# STM32L412C8T6 register map
File version: 1.0
Registers are 32-bit, access not given, reset 0x0 unless marked. A register's access mark holds for its fields unless they carry their own. Offsets are from the block's base; [hi:lo] are bit positions.

## RCC
Base 0x40021000
0x00 CR
  [27] PLLSAI1RDY, [26] PLLSAI1ON, [25] PLLRDY, [24] PLLON, [19] CSSON, [18] HSEBYP, [17] HSERDY, [16] HSEON, [31:12] s, [11] HSIASFS, [10] HSIRDY, [9] HSIKERON, [8] HSION, [7:4] MSIRANGE, [3] MSIRGSEL, [2] MSIPLLEN, [1] MSIRDY, [0] MSION
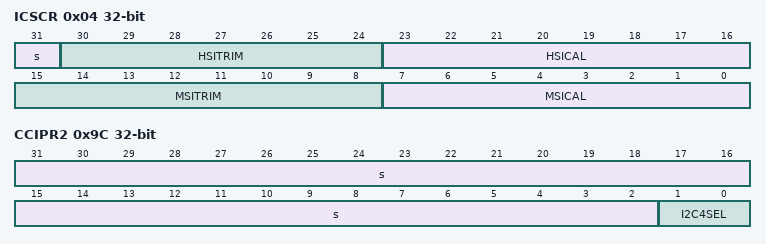
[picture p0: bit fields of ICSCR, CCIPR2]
0x04 ICSCR
  [31] s, [30:24] HSITRIM, [23:16] HSICAL, [15:8] MSITRIM, [7:0] MSICAL
0x08 CFGR
  [30:28] MCOPRE, [27:24] MCOSEL, [15] STOPWUCK, [31:14] s, [13:11] PPRE2, [10:8] PPRE1, [7:4] HPRE, [3:2] SWS, [1:0] SW
0x0C PLLCFGR
  [31:27] PLLPDIV, [26:25] PLLR, [24] PLLREN, [22:21] PLLQ, [20] PLLQEN, [17] PLLP, [16] PLLPEN, [14:8] PLLN, [6:4] PLLM, [23:2] s, [1:0] PLLSRC
0x10 PLLSAI1CFGR
  [31:27] PLLSAI1PDIV, [26:25] PLLSAI1R, [24] PLLSAI1REN, [22:21] PLLSAI1Q, [20] PLLSAI1QEN, [17] PLLSAI1P, [16] PLLSAI1PEN, [14:8] PLLSAI1N, [23:0] s
0x18 CIER
  [10] HSI48RDYIE, [9] LSECSSIE, [31:7] s, [6] PLLSAI1RDYIE, [5] PLLRDYIE, [4] HSERDYIE, [3] HSIRDYIE, [2] MSIRDYIE, [1] LSERDYIE, [0] LSIRDYIE
0x1C CIFR
  [10] HSI48RDYF, [9] LSECSSF, [8] CSSF, [31:7] s, [6] PLLSAI1RDYF, [5] PLLRDYF, [4] HSERDYF, [3] HSIRDYF, [2] MSIRDYF, [1] LSERDYF, [0] LSIRDYF
0x20 CICR
  [10] HSI48RDYC, [9] LSECSSC, [8] CSSC, [31:7] s, [6] PLLSAI1RDYC, [5] PLLRDYC, [4] HSERDYC, [3] HSIRDYC, [2] MSIRDYC, [1] LSERDYC, [0] LSIRDYC
0x28 AHB1RSTR
  [16] TSCRST, [12] CRCRST, [8] FLASHRST, [31:2] s, [1] DMA2RST, [0] DMA1RST
0x2C AHB2RSTR
  [18] RNGRST, [16] AESRST, [13] ADCRST, [7] GPIOHRST, [31:5] s, [4] GPIOERST, [3] GPIODRST, [2] GPIOCRST, [1] GPIOBRST, [0] GPIOARST
0x30 AHB3RSTR
  [8] QSPIRST, [31:0] s
0x38 APB1RSTR1
  [31] LPTIM1RST, [30] OPAMPRST, [29] DAC1RST, [28] PWRRST, [26] USBFSRST, [25] CAN1RST, [24] CRSRST, [23] I2C3RST, [22] I2C2RST, [21] I2C1RST, [19] UART4RST, [18] USART3RST, [17] USART2RST, [15] SPI3RST, [14] SPI2RST, [9] LCDRST, [5] TIM7RST, [4] TIM6RST, [27:2] s, [1] TIM3RST, [0] TIM2RST
0x3C APB1RSTR2
  [5] LPTIM2RST, [31:3] s, [2] SWPMI1RST, [1] I2C4RST, [0] LPUART1RST
0x40 APB2RSTR
  [24] DFSDM1RST, [21] SAI1RST, [17] TIM16RST, [16] TIM15RST, [14] USART1RST, [12] SPI1RST, [11] TIM1RST, [10] SDMMC1RST, [31:1] s, [0] SYSCFGRST
0x48 AHB1ENR
  [16] TSCEN, [12] CRCEN, [8] FLASHEN, [31:2] s, [1] DMA2EN, [0] DMA1EN
0x4C AHB2ENR
  [18] RNGEN, [16] AESEN, [13] ADCEN, [7] GPIOHEN, [31:5] s, [4] GPIOEEN, [3] GPIODEN, [2] GPIOCEN, [1] GPIOBEN, [0] GPIOAEN
0x50 AHB3ENR
  [8] QSPIEN, [31:1] s
0x58 APB1ENR1
  [31] LPTIM1EN, [30] OPAMPEN, [29] DAC1EN, [28] PWREN, [26] USBFSEN, [25] CAN1EN, [24] CRSEN, [23] I2C3EN, [22] I2C2EN, [21] I2C1EN, [19] UART4EN, [18] USART3EN, [17] USART2EN, [15] SP3EN, [14] SPI2EN, [11] WWDGEN, [10] RTCAPBEN, [9] LCDEN, [5] TIM7EN, [4] TIM6EN, [27:2] s, [1] TIM3EN, [0] TIM2EN
0x5C APB1ENR2
  [5] LPTIM2EN, [31:3] s, [2] SWPMI1EN, [1] I2C4EN, [0] LPUART1EN
0x60 APB2ENR
  [24] DFSDM1EN, [21] SAI1EN, [17] TIM16EN, [16] TIM15EN, [14] USART1EN, [12] SPI1EN, [11] TIM1EN, [10] SDMMC1EN, [7] FWEN, [31:1] s, [0] SYSCFGEN
0x68 AHB1SMENR
  [16] TSCSMEN, [12] CRCSMEN, [9] SRAM1SMEN, [8] FLASHSMEN, [31:2] s, [1] DMA2SMEN, [0] DMA1SMEN
0x6C AHB2SMENR
  [18] RNGSMEN, [16] AESSMEN, [13] ADCFSSMEN, [9] SRAM2SMEN, [7] GPIOHSMEN, [31:5] s, [4] GPIOESMEN, [3] GPIODSMEN, [2] GPIOCSMEN, [1] GPIOBSMEN, [0] GPIOASMEN
0x70 AHB3SMENR
  [8] QSPISMEN, [31:0] s
0x78 APB1SMENR1
  [31] LPTIM1SMEN, [30] OPAMPSMEN, [29] DAC1SMEN, [28] PWRSMEN, [26] USBFSSMEN, [25] CAN1SMEN, [24] CRSSMEN, [23] I2C3SMEN, [22] I2C2SMEN, [21] I2C1SMEN, [19] UART4SMEN, [18] USART3SMEN, [17] USART2SMEN, [15] SP3SMEN, [14] SPI2SMEN, [11] WWDGSMEN, [10] RTCAPBSMEN, [9] LCDSMEN, [5] TIM7SMEN, [4] TIM6SMEN, [27:2] s, [1] TIM3SMEN, [0] TIM2SMEN
0x7C APB1SMENR2
  [5] LPTIM2SMEN, [31:3] s, [2] SWPMI1SMEN, [1] I2C4SMEN, [0] LPUART1SMEN
0x80 APB2SMENR
  [24] DFSDM1SMEN, [21] SAI1SMEN, [17] TIM16SMEN, [16] TIM15SMEN, [14] USART1SMEN, [12] SPI1SMEN, [11] TIM1SMEN, [10] SDMMC1SMEN, [31:1] s, [0] SYSCFGSMEN
0x88 CCIPR
  [31] DFSDM1SEL, [30] SWPMI1SEL, [29:28] ADCSEL, [27:26] CLK48SEL, [23:22] SAI1SEL, [21:20] LPTIM2SEL, [19:18] LPTIM1SEL, [17:16] I2C3SEL, [15:14] I2C2SEL, [13:12] I2C1SEL, [11:10] LPUART1SEL, [25:8] s, [7:6] UART4SEL, [5:4] USART3SEL, [3:2] USART2SEL, [1:0] USART1SEL
0x90 BDCR
  [25] LSCOSEL, [24] LSCOEN, [16] BDRST, [15] RTCEN, [31:10] s, [9:8] RTCSEL, [7] LSESYSDIS, [6] LSECSSD, [5] LSECSSON, [4:3] LSEDRV, [2] LSEBYP, [1] LSERDY, [0] LSEON
0x94 CSR
  [31] LPWRRSTF, [30] WWDGRSTF, [29] IWDGRSTF, [28] SFTRSTF, [27] BORRSTF, [26] PINRSTF, [25] OBLRSTF, [24] FIREWALLRSTF, [23] RMVF, [11:8] MSISRANGE, [4] LSIPREDIV, [22:2] s, [1] LSIRDY, [0] LSION
0x98 CRRCR
  [15:7] HSI48CAL, [31:2] s, [1] HSI48RDY, [0] HSI48ON
0x9C CCIPR2
  [31:2] s, [1:0] I2C4SEL
